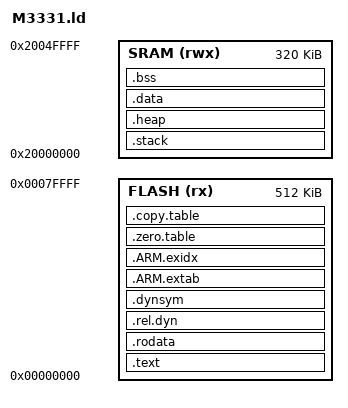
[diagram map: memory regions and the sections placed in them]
PROVIDE(__STACK_SIZE = 0x00001000);
PROVIDE(__HEAP_SIZE  = 0x00000000);

/* System memory brief */
MEMORY
{
  FLASH (rx)  : ORIGIN = 0x00000000, LENGTH = 0x80000    /* 512k */
  SRAM (rwx)  : ORIGIN = 0x20000000, LENGTH = 0x50000    /* 320k */
}


/* Linker script to place sections and symbol values. Should be used together
 * with other linker script that defines memory regions FLASH and RAM.
 * It references following symbols, which must be defined in code:
 *   Reset_Handler : Entry of reset handler
 *
 * It defines following symbols, which code can use without definition:
 *   __exidx_start
 *   __exidx_end
 *   __copy_table_start__
 *   __copy_table_end__
 *   __zero_table_start__
 *   __zero_table_end__
 *   __etext
 *   __data_start__
 *   __preinit_array_start
 *   __preinit_array_end
 *   __init_array_start
 *   __init_array_end
 *   __fini_array_start
 *   __fini_array_end
 *   __data_end__
 *   __bss_start__
 *   __bss_end__
 *   __end__
 *   end
 *   __HeapLimit
 *   __StackLimit
 *   __StackTop
 *   __stack
 */

ENTRY(Reset_Handler)

SECTIONS
{
  .text :
  {
    KEEP(*(.vectors))
    KEEP(*(CLINFO))
    *custom_loader.o(.text* .rodata*)
    *startup_*.o(.text*)

    *(.text*)

    KEEP(*(.init))
    KEEP(*(.fini))

    /* .ctors */
    *crtbegin.o(.ctors)
    *crtbegin?.o(.ctors)
    *(EXCLUDE_FILE(*crtend?.o *crtend.o) .ctors)
    *(SORT(.ctors.*))
    *(.ctors)

    /* .dtors */
    *crtbegin.o(.dtors)
    *crtbegin?.o(.dtors)
    *(EXCLUDE_FILE(*crtend?.o *crtend.o) .dtors)
    *(SORT(.dtors.*))
    *(.dtors)

    /* section information for finsh shell */
    . = ALIGN(4);
    __fsymtab_start = .;
    KEEP(*(FSymTab))
    __fsymtab_end = .;
    . = ALIGN(4);
    __vsymtab_start = .;
    KEEP(*(VSymTab))
    __vsymtab_end = .;
    . = ALIGN(4);

    /* section information for initial. */
    . = ALIGN(4);
    __rt_init_start = .;
    KEEP(*(SORT(.rti_fn*)))
    __rt_init_end = .;
    . = ALIGN(4);

    /* section information for utest */
    . = ALIGN(4);
    __rt_utest_tc_tab_start = .;
    KEEP(*(UtestTcTab))
    __rt_utest_tc_tab_end = .;

    /* section information for cherryusb usb host class */
    . = ALIGN(4);
    __usbh_class_info_start__ = .;
    KEEP(*(.usbh_class_info))
    __usbh_class_info_end__ = .;

    *(.ctors)

    /* NN-Model section */
    *(nn_model)

    /* Label section*/
    *(labels)

    /* Label section*/
    *(ifm)

    KEEP(*(.eh_frame*))
  } > FLASH

  .rodata : {
    . = ALIGN(8);
    *(.rodata*)
    . = ALIGN(8);
  } >FLASH

  .rel.dyn : {
    . = ALIGN(8);
    __rel_dyn_start = .;
    *(.rel*)
    __rel_dyn_end = .;
    . = ALIGN(8);
   } > FLASH

   .dynsym : {
     . = ALIGN(8);
     __dynsym_start = .;
     *(.dynsym)
     __dynsym_end = .;
     . = ALIGN(8);
    } > FLASH

  .ARM.extab :
  {
    *(.ARM.extab* .gnu.linkonce.armextab.*)
  } > FLASH

  .ARM.exidx :
  {
    __exidx_start = .;
    *(.ARM.exidx* .gnu.linkonce.armexidx.*)
    __exidx_end = .;
  } > FLASH

  .zero.table :
  {
    . = ALIGN(4);
    __zero_table_start__ = .;
    LONG (__bss_start__)
    LONG ((__bss_end__ - __bss_start__) / 4)
    __zero_table_end__ = .;
  } > FLASH

  .copy.table :
  {
    . = ALIGN(4);
    __copy_table_start__ = .;

    /* Section to be copied - part 1: RW data for SRAM */
    LONG (__etext)
    LONG (__data_start__)
    LONG ((__data_end__ - __data_start__) / 4)

    __copy_table_end__ = .;
  } > FLASH

  /**
   * Location counter can end up 2 byte aligned with narrow Thumb code but
   * __etext is assumed by startup code to be the LMA of a section
   * which must be 4byte aligned
   */
  __etext = ALIGN (4);

  .stack (ORIGIN(SRAM)) (NOLOAD) :
  {
    . = ALIGN(8);
    __StackLimit = .;
    . = . + __STACK_SIZE;
    . = ALIGN(8);
    __StackTop = .;
  } > SRAM
  PROVIDE(__stack = __StackTop);

  .heap (NOLOAD) :
  {
    . = ALIGN(8);
    __end__ = .;
    PROVIDE(end = .);
    . = . + __HEAP_SIZE;
    . = ALIGN(8);
    __HeapLimit = .;
  } > SRAM



  .data : AT (__etext)
  {
    __data_start__ = .;
    *(vtable)
    *(.data)
    *(.data.*)

    . = ALIGN(4);
    /* preinit data */
    PROVIDE_HIDDEN (__preinit_array_start = .);
    KEEP(*(.preinit_array))
    PROVIDE_HIDDEN (__preinit_array_end = .);

    . = ALIGN(4);
    PROVIDE(__ctors_start__ = .);
    /* init data */
    PROVIDE_HIDDEN (__init_array_start = .);
    KEEP(*(SORT(.init_array.*)))
    KEEP(*(.init_array))
    PROVIDE_HIDDEN (__init_array_end = .);
    PROVIDE(__ctors_end__ = .);

    . = ALIGN(4);
    /* finit data */
    PROVIDE_HIDDEN (__fini_array_start = .);
    KEEP(*(SORT(.fini_array.*)))
    KEEP(*(.fini_array))
    PROVIDE_HIDDEN (__fini_array_end = .);

    KEEP(*(.jcr*))
    . = ALIGN(4);
    /* All data end */
    __data_end__ = .;
  } > SRAM

  .bss :
  {
    . = ALIGN(4);
    __bss_start__ = .;
    *(.bss)
    *(.bss.*)
    *(COMMON)
    . = ALIGN(4);
    __bss_end__ = .;
  } > SRAM AT > SRAM
}
